# dim_example: IP-XACT component
VLNV Example:LibraryName:dim_example:Version

## Address spaces and blocks
memmap_example_dim.reg_dim: base 'h0, range 'h400, width 32
memmap_example_dim.file_reg_dim: base 'h400, range 'h400, width 32

## Registers
Registers are 32-bit, read-write, no defined reset value unless marked. A register's access mark holds for its fields unless they carry their own. Offsets are from the block's base; lines under a group give offsets from that group; [hi:lo] are bit positions; {n}, {i} and the like mark numbered series; 'fields as' and 'values as' point back to an identical list; <NAME> marks a mode.

## memmap_example_dim.reg_dim — Block 1 - With register Dim Example
Base 0x00000000
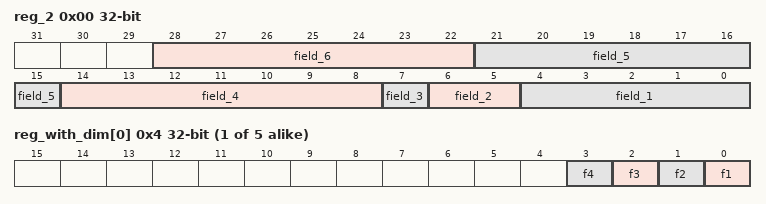
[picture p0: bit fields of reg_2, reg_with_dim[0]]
0x00 reg_2 — Description
  [28:22] field_6
  [21:15] field_5
  [14:8] field_4
  [7] field_3 — Description
  [6:5] field_2 — Description
  [4:0] field_1
{0x4+4i} reg_with_dim[{i}] (i=0..4)
  [n-1] f{n} (n=1..4) — Description
0x20 reg_3 ro
  [31:0] PN

## memmap_example_dim.file_reg_dim — Block 2 - With registerFile Dim Example
Base 0x00000400
{0x0+0x10*i} CHANNEL[{i}] (i=0..3) group — Channel Descriptor Registers
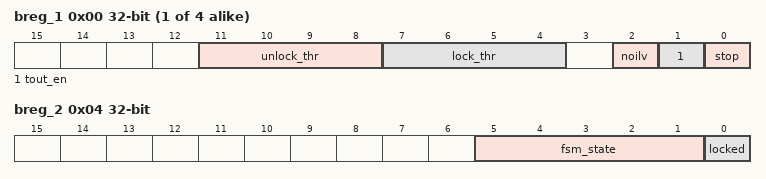
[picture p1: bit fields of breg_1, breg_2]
  0x00 breg_1 access not given — Description
    [11:8] unlock_thr — Description
    [7:4] lock_thr — Description
    [2] noilv — Description
    [1] tout_en — Description
    [0] stop — Description
0x04 breg_2 ro — Description
  [5:1] fsm_state — Description
  [0] locked — Description
